# R7FA6M4AF register map
Vendor: Renesas Electronics Corporation; Series: RA6; File version: 1.30.00
CPU: CM33 r0p4, little endian, MPU, FPU, VTOR, 4 interrupt priority bits, 96 interrupts
Registers are 8-bit, read-write, reset 0x0 unless marked. A register's access mark holds for its fields unless they carry their own. Offsets are from the block's base; [hi:lo] are bit positions; {n}, {i} and the like mark numbered series.

## DOC — Data Operation Circuit
Base 0x40109000
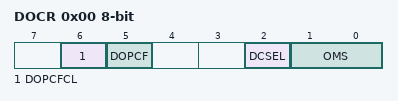
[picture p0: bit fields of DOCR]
0x00 DOCR — DOC Control Register
  [6] DOPCFCL — DOPCF Clear
  [5] DOPCF ro — DOC Flag
  [2] DCSEL — Detection Condition Select
  [1:0] OMS — Operating Mode Select
0x02 DODIR 16-bit — DOC Data Input Register
0x04 DODSR 16-bit — DOC Data Setting Register

## SPI0 — Serial Peripheral Interface 0
Base 0x4011A000
Same registers: SPI1 0x4011A100
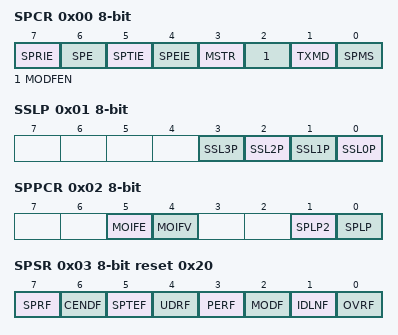
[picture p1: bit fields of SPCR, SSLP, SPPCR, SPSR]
0x00 SPCR — SPI Control Register
  [7] SPRIE — SPI Receive Buffer Full Interrupt Enable
  [6] SPE — SPI Function Enable
  [5] SPTIE — Transmit Buffer Empty Interrupt Enable
  [4] SPEIE — SPI Error Interrupt Enable
  [3] MSTR — SPI Master/Slave Mode Select
  [2] MODFEN — Mode Fault Error Detection Enable
  [1] TXMD — Communications Operating Mode Select
  [0] SPMS — SPI Mode Select
0x01 SSLP — SPI Slave Select Polarity Register
  [n] SSL{n}P (n=0..3) — SSLn{n} Signal Polarity Setting
0x02 SPPCR — SPI Pin Control Register
  [5] MOIFE — MOSI Idle Value Fixing Enable
  [4] MOIFV — MOSI Idle Fixed Value
  [1] SPLP2 — SPI Loopback 2
  [0] SPLP — SPI Loopback
0x03 SPSR reset 0x20 — SPI Status Register
  [7] SPRF — SPI Receive Buffer Full Flag
  [6] CENDF — Communication End Flag
  [5] SPTEF — SPI Transmit Buffer Empty Flag
  [4] UDRF — Underrun Error Flag
  [3] PERF — Parity Error Flag
  [2] MODF — Mode Fault Error Flag
  [1] IDLNF ro — SPI Idle Flag
  [0] OVRF — Overrun Error Flag
0x04 SPDR 32-bit — SPI Data Register
0x04 SPDR_HA 16-bit (alternate view of SPDR) — SPI Data Register
0x04 SPDR_BY (alternate view of SPDR) — SPI Data Register
0x08 SPSCR — SPI Sequence Control Register
  [2:0] SPSLN — SPI Sequence Length Specification
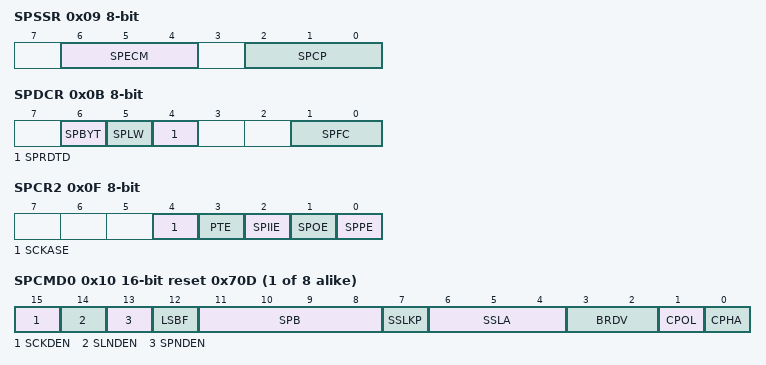
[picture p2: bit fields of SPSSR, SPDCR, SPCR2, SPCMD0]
0x09 SPSSR ro — SPI Sequence Status Register
  [6:4] SPECM — SPI Error Command
  [2:0] SPCP — SPI Command Pointer
0x0A SPBR reset 0xFF — SPI Bit Rate Register
0x0B SPDCR — SPI Data Control Register
  [6] SPBYT — SPI Byte Access Specification
  [5] SPLW — SPI Word Access/Halfword Access Specification
  [4] SPRDTD — SPI Receive/Transmit Data Select
  [1:0] SPFC — Number of Frames Specification
0x0C SPCKD — SPI Clock Delay Register
  [2:0] SCKDL — RSPCK Delay Setting
0x0D SSLND — SPI Slave Select Negation Delay Register
  [2:0] SLNDL — SSL Negation Delay Setting
0x0E SPND — SPI Next,Access Delay Register
  [2:0] SPNDL — SPI Next,Access Delay Setting
0x0F SPCR2 — SPI Control Register 2
  [4] SCKASE — RSPCK Auto,Stop Function Enable
  [3] PTE — Parity Self,Testing
  [2] SPIIE — SPI Idle Interrupt Enable
  [1] SPOE — Parity Mode
  [0] SPPE — Parity Enable
{0x10+2i} SPCMD{i} (i=0..7) 16-bit reset 0x70D — SPI Command Register {i}
  [15] SCKDEN — RSPCK Delay Setting Enable
  [14] SLNDEN — SSL Negation Delay Setting Enable
  [13] SPNDEN — SPI Next,Access Delay Enable
  [12] LSBF — SPI LSB First
  [11:8] SPB — SPI Data Length Setting
  [7] SSLKP — SSL Signal Level Keeping
  [6:4] SSLA — SSL Signal Assertion Setting
  [3:2] BRDV — Bit Rate Division Setting
  [1] CPOL — RSPCK Polarity Setting
  [0] CPHA — RSPCK Phase Setting
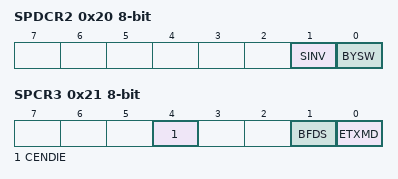
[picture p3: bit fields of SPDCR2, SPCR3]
0x20 SPDCR2 — SPI Data Control Register 2
  [1] SINV — Serial Data Invert Bit
  [0] BYSW — Byte Swap Operating Mode Select
0x21 SPCR3 — SPI Control Register 3
  [4] CENDIE — SPI Communication End Interrupt Enable
  [1] BFDS — Between Burst Transfer Frames Delay Select
  [0] ETXMD — Extended Communication Mode Select

## GPT_OPS — Output Phase Switching Controller
Base 0x40169A00
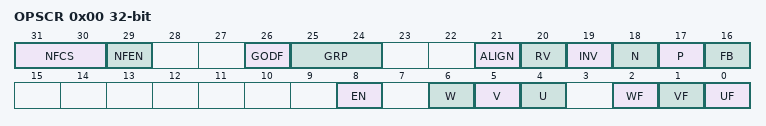
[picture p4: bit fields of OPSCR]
0x00 OPSCR 32-bit — Output Phase Switching Control Register
  [31:30] NFCS — External Input Noise Filter Clock Selection
  [29] NFEN — External Input Noise Filter Enable
  [26] GODF — Group Output Disable Function
  [25:24] GRP — Output Disabled Source Selection
  [21] ALIGN — Input Phase Alignment
  [20] RV — Output Phase Rotation Direction Reversal Control
  [19] INV — Output Phase Invert Control
  [18] N — Negative,Phase Output (N) Control
  [17] P — Positive,Phase Output (P) Control
  [16] FB — External Feedback Signal Enable
  [8] EN — Output Phase Enable
  [6] W ro — Input W,Phase Monitor
  [5] V ro — Input V,Phase Monitor
  [4] U ro — Input U,Phase Monitor
  [2] WF
  [1] VF
  [0] UF
